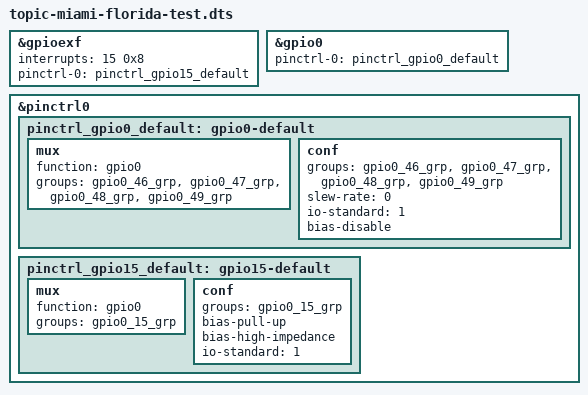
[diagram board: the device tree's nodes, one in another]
/dts-v1/;
/include/ "topic-miami.dtsi"
/include/ "topic-miami-florida-test.dtsi"

&gpioexf {
	/* IRQ line connected to MIO 15 */
	interrupts = <15 0x8>; /* GPIO 15, IRQ_TYPE_LEVEL_LOW */
	pinctrl-names = "default";
	pinctrl-0 = <&pinctrl_gpio15_default>;
};


/* The test board doesn't have PS JTAG, mux these pins as GPIO instead */
&gpio0 {
	pinctrl-names = "default";
	pinctrl-0 = <&pinctrl_gpio0_default>;
};

&pinctrl0 {
	pinctrl_gpio0_default: gpio0-default {
		mux {
			function = "gpio0";
			groups =
				"gpio0_46_grp",	"gpio0_47_grp",	"gpio0_48_grp",
				"gpio0_49_grp";
		};

		conf {
			groups =
				"gpio0_46_grp",	"gpio0_47_grp",	"gpio0_48_grp",
				"gpio0_49_grp";
			slew-rate = <0>;
			io-standard = <1>;
			bias-disable;
		};
	};

	pinctrl_gpio15_default: gpio15-default {
		mux {
			function = "gpio0";
			groups = "gpio0_15_grp";
		};

		conf {
			groups = "gpio0_15_grp";
			bias-pull-up;
			bias-high-impedance;
			io-standard = <1>;
		};
	};
};

